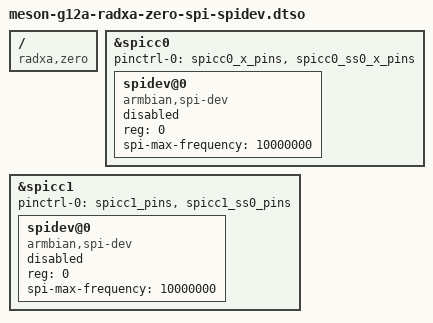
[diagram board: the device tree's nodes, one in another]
/dts-v1/;
/plugin/;

/ {
	compatible = "radxa,zero", "amlogic,g12a";
};

&spicc0 {
	pinctrl-0 = <&spicc0_x_pins &spicc0_ss0_x_pins>;
	pinctrl-names = "default";
	#address-cells = <1>;
	#size-cells = <0>;
	spidev@0 {
		compatible = "armbian,spi-dev";
		status = "disabled";
		reg = <0>;
		spi-max-frequency = <10000000>;
	};
};

&spicc1 {
	pinctrl-0 = <&spicc1_pins &spicc1_ss0_pins>;
	pinctrl-names = "default";
	#address-cells = <1>;
	#size-cells = <0>;
	spidev@0 {
		compatible = "armbian,spi-dev";
		status = "disabled";
		reg = <0>;
		spi-max-frequency = <10000000>;
	};
};
